# M55M1 register map
File version: 1.0
Registers are 32-bit, read-write, reset 0x0 unless marked. A register's access mark holds for its fields unless they carry their own. Offsets are from the block's base; [hi:lo] are bit positions.

## EQEI0 — EQEI Register Map
Base 0x40244000
Same registers: EQEI1 0x40245000, EQEI2 0x40284000, EQEI3 0x40285000, EQEI0_NS 0x50244000, EQEI1_NS 0x50245000, EQEI2_NS 0x50284000, EQEI3_NS 0x50285000
0x00 EQEI_CNT — EQEI Counter Register
  [31:0] CNT — Enhanced Quadrature Encoder Interface Counter. A 32-bit up/down counter. When an effective phase pulse is detected, this counter is increased by one if the bit DIRF (EQEI_STATUS[8]) is one or decreased by one if the bit DIRF(EQEI_STATUS[8]) is 0. This register performs an integrator which count value is proportional to the encoder position. The pulse counter may be initialized to a predetermined value by one of three events occurs:
0x04 EQEI_CNTHOLD — EQEI Counter Hold Register
  [31:0] CNTHOLD — Enhanced Quadrature Encoder Interface Counter Hold. When the bit HOLDCNT (EQEI_CTL[24]) goes from low to high, the CNT(EQEI_CNT[31:0]) is copied into CNTHOLD (EQEI_CNTHOLD[31:0]) register.
0x08 EQEI_CNTLATCH — EQEI Counter Index Latch Register
  [31:0] CNTLATCH — Enhanced Quadrature Encoder Interface Counter Index Latch. When the IDXF (EQEI_STATUS[0]) bit is set, the CNT(EQEI_CNT[31:0]) is copied into CNTLATCH (EQEI_CNTLATCH[31:0]) register.
0x0C EQEI_CNTCMP — EQEI Counter Compare Register
  [31:0] CNTCMP — Enhanced Quadrature Encoder Interface Counter Compare
0x14 EQEI_CNTMAX — EQEI Pre-set Maximum Count Register
  [31:0] CNTMAX — Enhanced Quadrature Encoder Interface Preset Maximum Count. This register value determined by user stores the maximum value which may be the number of the EQEI counter for the EQEI controller compare-counting mode.
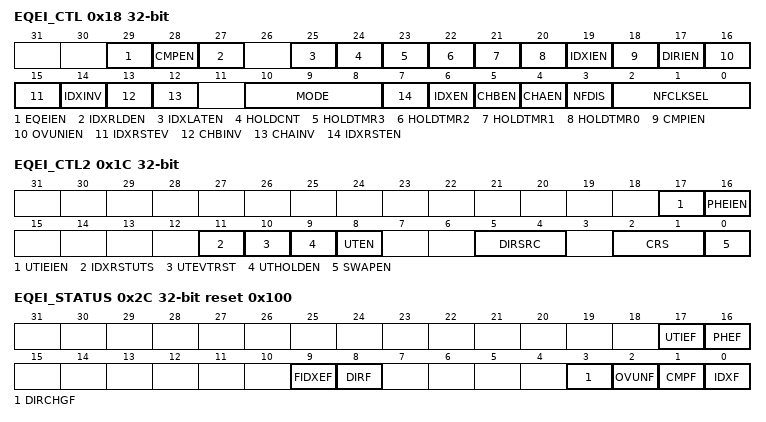
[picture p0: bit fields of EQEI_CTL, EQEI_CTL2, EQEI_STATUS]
0x18 EQEI_CTL — EQEI Controller Control Register
  [29] EQEIEN — Enhanced Quadrature Encoder Interface Controller Enable Bit
    0=EQEI controller function Disabled; 1=EQEI controller function Enabled
  [28] CMPEN — The Compare Function Enable Bit. The compare function in EQEI controller is to compare the dynamic counting EQEI_CNT with the compare register CNTCMP( EQEI_CNTCMP[31:0]), if CNT(EQEI_CNT[31:0]) reaches CNTCMP( EQEI_CNTCMP[31:0]), the flag CMPF will be set.
    0=Compare function Disabled; 1=Compare function Enabled
  [27] IDXRLDEN — Index Trigger EQEI_CNT Reload Enable Bit
    0=Reload function Disabled; 1=EQEI_CNT re-initialized by Index signal Enabled
  [25] IDXLATEN — Index Latch EQEI_CNT Enable Bit. If this bit is set to high, the CNT(EQEI_CNT[31:0]) content will be latched into CNTLATCH (EQEI_CNTLATCH[31:0]) at every rising on signal CHX.
    0=The index signal latch EQEI counter function Disabled; 1=The index signal latch EQEI counter function Enabled
  [24] HOLDCNT — Hold EQEI_CNT Control. When this bit is set from low to high, the CNT(EQEI_CNT[31:0]) is copied into CNTHOLD(EQEI_CNTHOLD[31:0]). This bit may be set by writing 1 to it or Timer0~Timer3 interrupt flag TIF (TIMERx_INTSTS[0]). Note: This bit is automatically cleared after EQEI_CNTHOLD holds EQEI_CNT value.
    0=No operation; 1=EQEI_CNT content is captured and stored in CNTHOLD(EQEI_CNTHOLD[31:0])
  [23] HOLDTMR3 — Hold EQEI_CNT by Timer 3
    0=TIF (TIMER3_INTSTS[0]) has no effect on HOLDCNT; 1=A rising edge of bit TIF(TIMER3_INTSTS[0]) in timer 3 sets HOLDCNT to 1
  [22] HOLDTMR2 — Hold EQEI_CNT by Timer 2
    0=TIF(TIMER2_INTSTS[0]) has no effect on HOLDCNT; 1=A rising edge of bit TIF(TIMER2_INTSTS[0]) in timer 2 sets HOLDCNT to 1
  [21] HOLDTMR1 — Hold EQEI_CNT by Timer 1
    0=TIF(TIMER1_INTSTS[0]) has no effect on HOLDCNT; 1=A rising edge of bit TIF (TIMER1_INTSTS[0]) in timer 1 sets HOLDCNT to 1
  [20] HOLDTMR0 — Hold EQEI_CNT by Timer 0
    0=TIF (TIMER0_INTSTS[0]) has no effect on HOLDCNT; 1=A rising edge of bit TIF(TIMER0_INTSTS[0]) in timer 0 sets HOLDCNT to 1
  [19] IDXIEN — IDXF Trigger EQEI Interrupt Enable Bit
    0=The IDXF can trigger EQEI interrupt Disabled; 1=The IDXF can trigger EQEI interrupt Enabled
  [18] CMPIEN — CMPF Trigger EQEI Interrupt Enable Bit
    0=CMPF can trigger EQEI controller interrupt Disabled; 1=CMPF can trigger EQEI controller interrupt Enabled
  [17] DIRIEN — DIRCHGF Trigger EQEI Interrupt Enable Bit
    0=DIRCHGF can trigger EQEI controller interrupt Disabled; 1=DIRCHGF can trigger EQEI controller interrupt Enabled
  [16] OVUNIEN — OVUNF Trigger EQEI Interrupt Enable Bit
    0=OVUNF can trigger EQEI controller interrupt Disabled; 1=OVUNF can trigger EQEI controller interrupt Enabled
  [15] IDXRSTEV wo — IDX Signal Resets Enable Bit in First IDX Reset Event (Write Only)
    0=The next IDX level high signal reset function Disabled; 1=The next IDX level high signal reset function Eenabled
  [14] IDXINV — Inverse IDX Input Polarity
    0=Not inverse IDX input polarity; 1=IDX input polarity is inversed to EQEI controller
  [13] CHBINV — Inverse QEB Input Polarity
    0=Not inverse QEB input polarity; 1=QEB input polarity is inversed to EQEI controller
  [12] CHAINV — Inverse QEA Input Polarity
    0=Not inverse QEA input polarity; 1=QEA input polarity is inversed to EQEI controller
  [10:8] MODE — EQEI Counting Mode Selection. There are seven quadrature encoder pulse counter operation modes. Note: User needs to set DIRSRC(EQEI_CTL2[5:4]) when MODE(EQEI_CTL[10:8]) selects to directional counting mode.
    0=X4 Free-counting Mode; 1=X2 Free-counting Mode; 2=X4 Compare-counting Mode; 3=X2 Compare-counting Mode; 4=Phase Counting Mode Type 1. (PCMT1); 5=Phase Counting Mode Type 2. (PCMT2); 6=Directional Counting Mode
  [7] IDXRSTEN — IDX Reset EQEI Position Counter Enable Bit. Note: IDXRLDEN(EQEI_CTL[27]) should be set 1.
    0=Reset EQEI position counter in every time IDX signal; 1=Reset EQEI position counter in first time IDX signal
  [6] IDXEN — IDX Input to EQEI Controller Enable Bit
    0=IDX input to EQEI Controller Disabled; 1=IDX input to EQEI Controller Enabled
  [5] CHBEN — QEB Input to EQEI Controller Enable Bit
    0=QEB input to EQEI Controller Disabled; 1=QEB input to EQEI Controller Enabled
  [4] CHAEN — QEA Input to EQEI Controller Enable Bit
    0=QEA input to EQEI Controller Disabled; 1=QEA input to EQEI Controller Enabled
  [3] NFDIS — EQEI Controller Input Noise Filter Disable Bit
    0=The noise filter of EQEI controller Enabled; 1=The noise filter of EQEI controller Disabled
  [2:0] NFCLKSEL — Noise Filter Clock Pre-divide Selection. To determine the sampling frequency of the Noise Filter clock.
    0=EQEI_CLK; 1=EQEI_CLK/2; 2=EQEI_CLK/4; 3=EQEI_CLK/16; 4=EQEI_CLK/32; 5=EQEI_CLK/64
0x1C EQEI_CTL2 — EQEI Controller Control Register2
  [17] UTIEIEN — UTIEF Trigger EQEI Interrupt Enable Bit
    0=UTIEF can trigger EQEI controller interrupt Disabled; 1=UTIEF can trigger EQEI controller interrupt Enabled
  [16] PHEIEN — PHEF Trigger EQEI Interrupt Enable Bit
    0=PHEF can trigger EQEI controller interrupt Disabled; 1=PHEF can trigger EQEI controller interrupt Enabled
  [11] IDXRSTUTS — IDX Resets Unit Timer Select Bit
    0=Unit timer will not be reset when IDX reset event happens; 1=Resets unit timer or not will follow EQEI_CNT when IDX reset event happens
  [10] UTEVTRST — Enable Bit to Reset EQEI Position Counter by Unit Timer Event
    0=Reset EQEI position counter feature when unit timer counter event occurs Disabled; 1=Reset EQEI position counter feature when unit timer counter event occurs Enabled
  [9] UTHOLDEN — Unit Timer Counter Hold Enable Bit
    0=No operation; 1=EQEI_CNT content is captured and stored in CNTHOLD(EQEI_CNTHOLD[31:0]) when UTCNT matches UTCMP(EQEI_UTCMP[31:0])
  [8] UTEN — Unit Timer Function Enable Bit
    0=EQEI unit timer function Disabled; 1=EQEI unit timer function Enabled
  [5:4] DIRSRC — Direction Signal Source Select
    0=Direction signal is determined from EQEI system calculation; 2=Direction signal is tied 1 only for direction up count mode; 3=Direction signal is tied 0 only for down count mode
  [2:1] CRS — Clock Rate Setting without Quadrature Mode
    0=EQEI counter only counts the falling edge; 1=EQEI counter only counts the rising edge; 2=EQEI counter counts the rising and falling edge
  [0] SWAPEN — Swap Function Enable Bit
    0=EQEI swap function Disabled; 1=EQEI swap function Enabled
0x20 EQEI_UTCNT — EQEI Unit Timer Counter Register
  [31:0] UTCNT — Unit Timer Counter. A 32-bit unit timer counter which may be reset to an initial value when any of the following events occur:
0x24 EQEI_UTCMP reset 0xFFFFFFFF — EQEI Unit Timer Compare Register
  [31:0] UTCMP — Unit Timer Counter Compare
0x2C EQEI_STATUS reset 0x100 — EQEI Controller Status Register
  [17] UTIEF — EQEI Unit Timer Event Flag. Note: This bit is only cleared by writing 1 to it.
    0=No timer event occurs in EQEI unit timer counter; 1=Unit timer event occurs in EQEI unit timer counter
  [16] PHEF — EQEI Phase Error Flag. Note: This bit is only cleared by writing 1 to it.
    0=No Phase error occurs in EQEI CHA and CHB; 1=Phase error occurs in EQEI CHA and CHB
  [9] FIDXEF ro — First IDX Signal Reset Event Flag (Read Only)
    0=The first IDX reset event has not happened yet; 1=The first IDX reset event has happened
  [8] DIRF — EQEI Counter Counting Direction Indication. Note: This bit is set/reset by hardware according to the phase detection between CHA and CHB.
    0=EQEI Counter is in down-counting; 1=EQEI Counter is in up-counting
  [3] DIRCHGF — Direction Change Flag. Flag is set by hardware while EQEI counter counting direction is changed. Software can clear this bit by writing 1 to it. Note: This bit is only cleared by writing 1 to it.
    0=No change in EQEI counter counting direction; 1=EQEI counter counting direction is changed
  [2] OVUNF — EQEI Counter Overflow or Underflow Flag. Flag is set by hardware while CNT(EQEI_CNT[31:0]) overflows from 0xFFFF_FFFF to 0 in free-counting mode or from the CNTMAX (EQEI_CNTMAX[31:0]) to 0 in compare-counting mode. Similarly, the flag is set while EQEI counter underflows from 0 to 0xFFFF_FFFF or CNTMAX (EQEI_CNTMAX[31:0]). Note: This bit is only cleared by writing 1 to it.
    0=No overflow or underflow occurs in EQEI counter; 1=EQEI counter occurs counting overflow or underflow
  [1] CMPF — Compare-match Flag. If the EQEI compare function is enabled, the flag is set by hardware while EQEI counter up or down counts and reach to the CNTCMP(EQEI_CNTCMP[31:0]). Note: This bit is only cleared by writing 1 to it.
    0=EQEI counter does not match with CNTCMP(EQEI_CNTCMP[31:0]); 1=EQEI counter counts to the same as CNTCMP(EQEI_CNTCMP[31:0])
  [0] IDXF — IDX Detected Flag. When the EQEI controller detects a rising edge on signal CHX it will set flag IDXF to high. Note: This bit is only cleared by writing 1 to it.
    0=No rising edge detected on signal CHX; 1=A rising edge occurs on signal CHX
